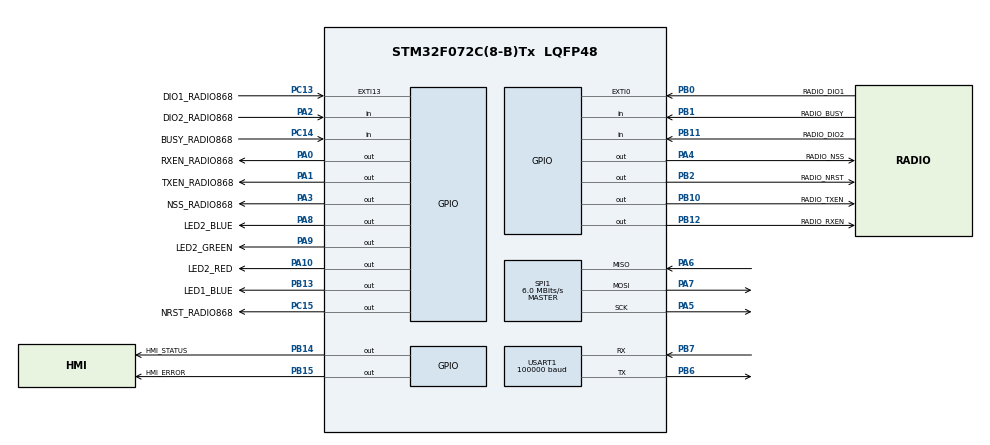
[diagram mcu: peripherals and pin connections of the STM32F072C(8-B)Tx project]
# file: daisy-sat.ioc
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Mcu.Family=STM32F0
Mcu.Name=STM32F072C(8-B)Tx
Mcu.Package=LQFP48
NVIC.EXTI0_1_IRQn=true\:0\:0\:false\:false\:false\:true\:false
NVIC.EXTI4_15_IRQn=true\:0\:0\:false\:false\:true\:true\:false
NVIC.USART1_IRQn=true\:0\:0\:false\:false\:false\:true\:false
PA0.GPIO_Label=RXEN_RADIO868
PA0.Signal=GPIO_Output
PA1.GPIO_Label=TXEN_RADIO868
PA1.Signal=GPIO_Output
PA10.GPIO_Label=LED2_RED
PA10.Signal=GPIO_Output
PA13.Mode=Serial_Wire
PA13.Signal=SYS_SWDIO
PA14.Mode=Serial_Wire
PA14.Signal=SYS_SWCLK
PA2.GPIO_Label=DIO2_RADIO868
PA2.GPIO_PuPd=GPIO_PULLUP
PA2.Signal=GPIO_Input
PA3.GPIO_Label=NSS_RADIO868
PA3.PinState=GPIO_PIN_SET
PA3.Signal=GPIO_Output
PA4.GPIO_Label=RADIO_NSS
PA4.PinState=GPIO_PIN_SET
PA4.Signal=GPIO_Output
PA5.Mode=Full_Duplex_Master
PA5.Signal=SPI1_SCK
PA6.GPIO_PuPd=GPIO_PULLUP
PA6.Mode=Full_Duplex_Master
PA6.Signal=SPI1_MISO
PA7.Mode=Full_Duplex_Master
PA7.Signal=SPI1_MOSI
PA8.GPIO_Label=LED2_BLUE
PA8.Signal=GPIO_Output
PA9.GPIO_Label=LED2_GREEN
PA9.Signal=GPIO_Output
PB0.GPIO_Label=RADIO_DIO1
PB0.GPIO_ModeDefaultEXTI=GPIO_MODE_IT_RISING
PB0.GPIO_PuPd=GPIO_PULLDOWN
PB0.Signal=GPXTI0
PB1.GPIO_Label=RADIO_BUSY
PB1.Signal=GPIO_Input
PB10.GPIO_Label=RADIO_TXEN
PB10.Signal=GPIO_Output
PB11.GPIO_Label=RADIO_DIO2
PB11.GPIO_PuPd=GPIO_PULLUP
PB11.Signal=GPIO_Input
PB12.GPIO_Label=RADIO_RXEN
PB12.Signal=GPIO_Output
PB13.GPIO_Label=LED1_BLUE
PB13.Signal=GPIO_Output
PB14.GPIO_Label=HMI_STATUS
PB14.Signal=GPIO_Output
PB15.GPIO_Label=HMI_ERROR
PB15.Signal=GPIO_Output
PB2.GPIO_Label=RADIO_NRST
PB2.Signal=GPIO_Output
PB6.Mode=Asynchronous
PB6.Signal=USART1_TX
PB7.GPIO_PuPd=GPIO_PULLUP
PB7.Mode=Asynchronous
PB7.Signal=USART1_RX
PC13.GPIO_Label=DIO1_RADIO868
PC13.GPIO_ModeDefaultEXTI=GPIO_MODE_IT_RISING
PC13.GPIO_PuPd=GPIO_PULLDOWN
PC13.Signal=GPXTI13
PC14-OSC32_IN.GPIO_Label=BUSY_RADIO868
PC14-OSC32_IN.Signal=GPIO_Input
PC15-OSC32_OUT.GPIO_Label=NRST_RADIO868
PC15-OSC32_OUT.Signal=GPIO_Output
ProjectManager.HeapSize=0x200
ProjectManager.StackSize=0x400
ProjectManager.TargetToolchain=STM32CubeIDE
RCC.AHBFreq_Value=48000000
RCC.APB1Freq_Value=48000000
RCC.APB1TimFreq_Value=48000000
RCC.HCLKFreq_Value=48000000
RCC.SYSCLKFreq_VALUE=48000000
RCC.SYSCLKSource=RCC_SYSCLKSOURCE_HSI48
SPI1.BaudRatePrescaler=SPI_BAUDRATEPRESCALER_8
SPI1.CalculateBaudRate=6.0 MBits/s
SPI1.DataSize=SPI_DATASIZE_8BIT
SPI1.Direction=SPI_DIRECTION_2LINES
SPI1.Mode=SPI_MODE_MASTER
SPI1.VirtualType=VM_MASTER
USART1.BaudRate=100000
USART1.OverrunDisableParam=ADVFEATURE_OVERRUN_ENABLE
USART1.Parity=PARITY_EVEN
USART1.RxPinLevelInvertParam=ADVFEATURE_RXINV_ENABLE
USART1.StopBits=STOPBITS_2
USART1.TxPinLevelInvertParam=ADVFEATURE_TXINV_ENABLE
USART1.VirtualMode-Asynchronous=VM_ASYNC
USART1.WordLength=WORDLENGTH_9B
VP_CRC_VS_CRC.Mode=CRC_Activate
board=custom

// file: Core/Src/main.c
/* USER CODE BEGIN Header */
/**
  ******************************************************************************
  * @file           : main.c
  * @brief          : Main program body
  ******************************************************************************
  * @attention
  *
  * <h2><center>&copy; Copyright (c) 2020 STMicroelectronics.
  * All rights reserved.</center></h2>
  *
  * This software component is licensed by ST under Ultimate Liberty license
  * SLA0044, the "License"; You may not use this file except in compliance with
  * the License. You may obtain a copy of the License at:
  *                             www.st.com/SLA0044
  *
  ******************************************************************************
  */
/* USER CODE END Header */
#include "main.h"

void SystemClock_Config(void);
static void MX_GPIO_Init(void);
static void MX_SPI1_Init(void);
static void MX_USART1_UART_Init(void);
static void MX_CRC_Init(void);

int main(void)
{

  /* MCU Configuration--------------------------------------------------------*/

  /* Reset of all peripherals, Initializes the Flash interface and the Systick. */

  LL_APB1_GRP2_EnableClock(LL_APB1_GRP2_PERIPH_SYSCFG);
  LL_APB1_GRP1_EnableClock(LL_APB1_GRP1_PERIPH_PWR);

  /* System interrupt init*/

  /* Configure the system clock */
  SystemClock_Config();

  /* Initialize all configured peripherals */
  MX_GPIO_Init();
  MX_SPI1_Init();
  MX_USART1_UART_Init();
  MX_CRC_Init();
  /* USER CODE BEGIN 2 */
  extern void RosalynSatSetup( void );
  RosalynSatSetup();
  /* USER CODE END 2 */

  /* Infinite loop */
  while (1)
  {

    /* USER CODE BEGIN 3 */
    extern void RosalynSatLoop( void );
    RosalynSatLoop();
  }
  /* USER CODE END 3 */
}

void SystemClock_Config(void)
{
  LL_FLASH_SetLatency(LL_FLASH_LATENCY_1);
  while(LL_FLASH_GetLatency() != LL_FLASH_LATENCY_1)
  {
  }
  LL_RCC_HSI48_Enable();

   /* Wait till HSI48 is ready */
  while(LL_RCC_HSI48_IsReady() != 1)
  {

  }
  LL_RCC_SetAHBPrescaler(LL_RCC_SYSCLK_DIV_1);
  LL_RCC_SetAPB1Prescaler(LL_RCC_APB1_DIV_1);
  LL_RCC_SetSysClkSource(LL_RCC_SYS_CLKSOURCE_HSI48);

   /* Wait till System clock is ready */
  while(LL_RCC_GetSysClkSource() != LL_RCC_SYS_CLKSOURCE_STATUS_HSI48)
  {

  }
  LL_Init1msTick(48000000);
  LL_SetSystemCoreClock(48000000);
  LL_RCC_SetUSARTClockSource(LL_RCC_USART1_CLKSOURCE_PCLK1);
}

static void MX_CRC_Init(void)
{

  /* Peripheral clock enable */
  LL_AHB1_GRP1_EnableClock(LL_AHB1_GRP1_PERIPH_CRC);

  LL_CRC_SetInputDataReverseMode(CRC, LL_CRC_INDATA_REVERSE_NONE);
  LL_CRC_SetOutputDataReverseMode(CRC, LL_CRC_OUTDATA_REVERSE_NONE);
  LL_CRC_SetInitialData(CRC, LL_CRC_DEFAULT_CRC_INITVALUE);

}

static void MX_SPI1_Init(void)
{

  LL_SPI_InitTypeDef SPI_InitStruct = {0};

  LL_GPIO_InitTypeDef GPIO_InitStruct = {0};

  /* Peripheral clock enable */
  LL_APB1_GRP2_EnableClock(LL_APB1_GRP2_PERIPH_SPI1);

  LL_AHB1_GRP1_EnableClock(LL_AHB1_GRP1_PERIPH_GPIOA);
  /**SPI1 GPIO Configuration
  PA5   ------> SPI1_SCK
  PA6   ------> SPI1_MISO
  PA7   ------> SPI1_MOSI
  */
  GPIO_InitStruct.Pin = LL_GPIO_PIN_5;
  GPIO_InitStruct.Mode = LL_GPIO_MODE_ALTERNATE;
  GPIO_InitStruct.Speed = LL_GPIO_SPEED_FREQ_HIGH;
  GPIO_InitStruct.OutputType = LL_GPIO_OUTPUT_PUSHPULL;
  GPIO_InitStruct.Pull = LL_GPIO_PULL_NO;
  GPIO_InitStruct.Alternate = LL_GPIO_AF_0;
  LL_GPIO_Init(GPIOA, &GPIO_InitStruct);

  GPIO_InitStruct.Pin = LL_GPIO_PIN_6;
  GPIO_InitStruct.Mode = LL_GPIO_MODE_ALTERNATE;
  GPIO_InitStruct.Speed = LL_GPIO_SPEED_FREQ_HIGH;
  GPIO_InitStruct.OutputType = LL_GPIO_OUTPUT_PUSHPULL;
  GPIO_InitStruct.Pull = LL_GPIO_PULL_UP;
  GPIO_InitStruct.Alternate = LL_GPIO_AF_0;
  LL_GPIO_Init(GPIOA, &GPIO_InitStruct);

  GPIO_InitStruct.Pin = LL_GPIO_PIN_7;
  GPIO_InitStruct.Mode = LL_GPIO_MODE_ALTERNATE;
  GPIO_InitStruct.Speed = LL_GPIO_SPEED_FREQ_HIGH;
  GPIO_InitStruct.OutputType = LL_GPIO_OUTPUT_PUSHPULL;
  GPIO_InitStruct.Pull = LL_GPIO_PULL_NO;
  GPIO_InitStruct.Alternate = LL_GPIO_AF_0;
  LL_GPIO_Init(GPIOA, &GPIO_InitStruct);

  /* SPI1 parameter configuration*/
  SPI_InitStruct.TransferDirection = LL_SPI_FULL_DUPLEX;
  SPI_InitStruct.Mode = LL_SPI_MODE_MASTER;
  SPI_InitStruct.DataWidth = LL_SPI_DATAWIDTH_8BIT;
  SPI_InitStruct.ClockPolarity = LL_SPI_POLARITY_LOW;
  SPI_InitStruct.ClockPhase = LL_SPI_PHASE_1EDGE;
  SPI_InitStruct.NSS = LL_SPI_NSS_SOFT;
  SPI_InitStruct.BaudRate = LL_SPI_BAUDRATEPRESCALER_DIV8;
  SPI_InitStruct.BitOrder = LL_SPI_MSB_FIRST;
  SPI_InitStruct.CRCCalculation = LL_SPI_CRCCALCULATION_DISABLE;
  SPI_InitStruct.CRCPoly = 7;
  LL_SPI_Init(SPI1, &SPI_InitStruct);
  LL_SPI_SetStandard(SPI1, LL_SPI_PROTOCOL_MOTOROLA);
  LL_SPI_EnableNSSPulseMgt(SPI1);

}

static void MX_USART1_UART_Init(void)
{

  LL_USART_InitTypeDef USART_InitStruct = {0};

  LL_GPIO_InitTypeDef GPIO_InitStruct = {0};

  /* Peripheral clock enable */
  LL_APB1_GRP2_EnableClock(LL_APB1_GRP2_PERIPH_USART1);

  LL_AHB1_GRP1_EnableClock(LL_AHB1_GRP1_PERIPH_GPIOB);
  /**USART1 GPIO Configuration
  PB6   ------> USART1_TX
  PB7   ------> USART1_RX
  */
  GPIO_InitStruct.Pin = LL_GPIO_PIN_6;
  GPIO_InitStruct.Mode = LL_GPIO_MODE_ALTERNATE;
  GPIO_InitStruct.Speed = LL_GPIO_SPEED_FREQ_HIGH;
  GPIO_InitStruct.OutputType = LL_GPIO_OUTPUT_PUSHPULL;
  GPIO_InitStruct.Pull = LL_GPIO_PULL_NO;
  GPIO_InitStruct.Alternate = LL_GPIO_AF_0;
  LL_GPIO_Init(GPIOB, &GPIO_InitStruct);

  GPIO_InitStruct.Pin = LL_GPIO_PIN_7;
  GPIO_InitStruct.Mode = LL_GPIO_MODE_ALTERNATE;
  GPIO_InitStruct.Speed = LL_GPIO_SPEED_FREQ_HIGH;
  GPIO_InitStruct.OutputType = LL_GPIO_OUTPUT_PUSHPULL;
  GPIO_InitStruct.Pull = LL_GPIO_PULL_UP;
  GPIO_InitStruct.Alternate = LL_GPIO_AF_0;
  LL_GPIO_Init(GPIOB, &GPIO_InitStruct);

  /* USART1 interrupt Init */
  NVIC_SetPriority(USART1_IRQn, 0);
  NVIC_EnableIRQ(USART1_IRQn);

  USART_InitStruct.BaudRate = 100000;
  USART_InitStruct.DataWidth = LL_USART_DATAWIDTH_9B;
  USART_InitStruct.StopBits = LL_USART_STOPBITS_2;
  USART_InitStruct.Parity = LL_USART_PARITY_EVEN;
  USART_InitStruct.TransferDirection = LL_USART_DIRECTION_TX_RX;
  USART_InitStruct.HardwareFlowControl = LL_USART_HWCONTROL_NONE;
  USART_InitStruct.OverSampling = LL_USART_OVERSAMPLING_16;
  LL_USART_Init(USART1, &USART_InitStruct);
  LL_USART_DisableIT_CTS(USART1);
  LL_USART_SetRXPinLevel(USART1, LL_USART_RXPIN_LEVEL_INVERTED);
  LL_USART_SetTXPinLevel(USART1, LL_USART_TXPIN_LEVEL_INVERTED);
  LL_USART_ConfigAsyncMode(USART1);
  LL_USART_Enable(USART1);

}

static void MX_GPIO_Init(void)
{
  LL_EXTI_InitTypeDef EXTI_InitStruct = {0};
  LL_GPIO_InitTypeDef GPIO_InitStruct = {0};

  /* GPIO Ports Clock Enable */
  LL_AHB1_GRP1_EnableClock(LL_AHB1_GRP1_PERIPH_GPIOC);
  LL_AHB1_GRP1_EnableClock(LL_AHB1_GRP1_PERIPH_GPIOF);
  LL_AHB1_GRP1_EnableClock(LL_AHB1_GRP1_PERIPH_GPIOA);
  LL_AHB1_GRP1_EnableClock(LL_AHB1_GRP1_PERIPH_GPIOB);

  /**/
  LL_GPIO_ResetOutputPin(NRST_RADIO868_GPIO_Port, NRST_RADIO868_Pin);

  /**/
  LL_GPIO_ResetOutputPin(RXEN_RADIO868_GPIO_Port, RXEN_RADIO868_Pin);

  /**/
  LL_GPIO_ResetOutputPin(TXEN_RADIO868_GPIO_Port, TXEN_RADIO868_Pin);

  /**/
  LL_GPIO_ResetOutputPin(RADIO_NRST_GPIO_Port, RADIO_NRST_Pin);

  /**/
  LL_GPIO_ResetOutputPin(RADIO_TXEN_GPIO_Port, RADIO_TXEN_Pin);

  /**/
  LL_GPIO_ResetOutputPin(RADIO_RXEN_GPIO_Port, RADIO_RXEN_Pin);

  /**/
  LL_GPIO_ResetOutputPin(LED1_BLUE_GPIO_Port, LED1_BLUE_Pin);

  /**/
  LL_GPIO_ResetOutputPin(HMI_STATUS_GPIO_Port, HMI_STATUS_Pin);

  /**/
  LL_GPIO_ResetOutputPin(HMI_ERROR_GPIO_Port, HMI_ERROR_Pin);

  /**/
  LL_GPIO_ResetOutputPin(LED2_BLUE_GPIO_Port, LED2_BLUE_Pin);

  /**/
  LL_GPIO_ResetOutputPin(LED2_GREEN_GPIO_Port, LED2_GREEN_Pin);

  /**/
  LL_GPIO_ResetOutputPin(LED2_RED_GPIO_Port, LED2_RED_Pin);

  /**/
  LL_GPIO_SetOutputPin(NSS_RADIO868_GPIO_Port, NSS_RADIO868_Pin);

  /**/
  LL_GPIO_SetOutputPin(RADIO_NSS_GPIO_Port, RADIO_NSS_Pin);

  /**/
  LL_SYSCFG_SetEXTISource(LL_SYSCFG_EXTI_PORTC, LL_SYSCFG_EXTI_LINE13);

  /**/
  LL_SYSCFG_SetEXTISource(LL_SYSCFG_EXTI_PORTB, LL_SYSCFG_EXTI_LINE0);

  /**/
  LL_GPIO_SetPinPull(DIO1_RADIO868_GPIO_Port, DIO1_RADIO868_Pin, LL_GPIO_PULL_DOWN);

  /**/
  LL_GPIO_SetPinPull(RADIO_DIO1_GPIO_Port, RADIO_DIO1_Pin, LL_GPIO_PULL_DOWN);

  /**/
  LL_GPIO_SetPinMode(DIO1_RADIO868_GPIO_Port, DIO1_RADIO868_Pin, LL_GPIO_MODE_INPUT);

  /**/
  LL_GPIO_SetPinMode(RADIO_DIO1_GPIO_Port, RADIO_DIO1_Pin, LL_GPIO_MODE_INPUT);

  /**/
  EXTI_InitStruct.Line_0_31 = LL_EXTI_LINE_13;
  EXTI_InitStruct.LineCommand = ENABLE;
  EXTI_InitStruct.Mode = LL_EXTI_MODE_IT;
  EXTI_InitStruct.Trigger = LL_EXTI_TRIGGER_RISING;
  LL_EXTI_Init(&EXTI_InitStruct);

  /**/
  EXTI_InitStruct.Line_0_31 = LL_EXTI_LINE_0;
  EXTI_InitStruct.LineCommand = ENABLE;
  EXTI_InitStruct.Mode = LL_EXTI_MODE_IT;
  EXTI_InitStruct.Trigger = LL_EXTI_TRIGGER_RISING;
  LL_EXTI_Init(&EXTI_InitStruct);

  /**/
  GPIO_InitStruct.Pin = BUSY_RADIO868_Pin;
  GPIO_InitStruct.Mode = LL_GPIO_MODE_INPUT;
  GPIO_InitStruct.Pull = LL_GPIO_PULL_NO;
  LL_GPIO_Init(BUSY_RADIO868_GPIO_Port, &GPIO_InitStruct);

  /**/
  GPIO_InitStruct.Pin = NRST_RADIO868_Pin;
  GPIO_InitStruct.Mode = LL_GPIO_MODE_OUTPUT;
  GPIO_InitStruct.Speed = LL_GPIO_SPEED_FREQ_LOW;
  GPIO_InitStruct.OutputType = LL_GPIO_OUTPUT_PUSHPULL;
  GPIO_InitStruct.Pull = LL_GPIO_PULL_NO;
  LL_GPIO_Init(NRST_RADIO868_GPIO_Port, &GPIO_InitStruct);

  /**/
  GPIO_InitStruct.Pin = LL_GPIO_PIN_0;
  GPIO_InitStruct.Mode = LL_GPIO_MODE_ANALOG;
  GPIO_InitStruct.Pull = LL_GPIO_PULL_NO;
  LL_GPIO_Init(GPIOF, &GPIO_InitStruct);

  /**/
  GPIO_InitStruct.Pin = LL_GPIO_PIN_1;
  GPIO_InitStruct.Mode = LL_GPIO_MODE_ANALOG;
  GPIO_InitStruct.Pull = LL_GPIO_PULL_NO;
  LL_GPIO_Init(GPIOF, &GPIO_InitStruct);

  /**/
  GPIO_InitStruct.Pin = RXEN_RADIO868_Pin;
  GPIO_InitStruct.Mode = LL_GPIO_MODE_OUTPUT;
  GPIO_InitStruct.Speed = LL_GPIO_SPEED_FREQ_LOW;
  GPIO_InitStruct.OutputType = LL_GPIO_OUTPUT_PUSHPULL;
  GPIO_InitStruct.Pull = LL_GPIO_PULL_NO;
  LL_GPIO_Init(RXEN_RADIO868_GPIO_Port, &GPIO_InitStruct);

  /**/
  GPIO_InitStruct.Pin = TXEN_RADIO868_Pin;
  GPIO_InitStruct.Mode = LL_GPIO_MODE_OUTPUT;
  GPIO_InitStruct.Speed = LL_GPIO_SPEED_FREQ_LOW;
  GPIO_InitStruct.OutputType = LL_GPIO_OUTPUT_PUSHPULL;
  GPIO_InitStruct.Pull = LL_GPIO_PULL_NO;
  LL_GPIO_Init(TXEN_RADIO868_GPIO_Port, &GPIO_InitStruct);

  /**/
  GPIO_InitStruct.Pin = DIO2_RADIO868_Pin;
  GPIO_InitStruct.Mode = LL_GPIO_MODE_INPUT;
  GPIO_InitStruct.Pull = LL_GPIO_PULL_UP;
  LL_GPIO_Init(DIO2_RADIO868_GPIO_Port, &GPIO_InitStruct);

  /**/
  GPIO_InitStruct.Pin = NSS_RADIO868_Pin;
  GPIO_InitStruct.Mode = LL_GPIO_MODE_OUTPUT;
  GPIO_InitStruct.Speed = LL_GPIO_SPEED_FREQ_LOW;
  GPIO_InitStruct.OutputType = LL_GPIO_OUTPUT_PUSHPULL;
  GPIO_InitStruct.Pull = LL_GPIO_PULL_NO;
  LL_GPIO_Init(NSS_RADIO868_GPIO_Port, &GPIO_InitStruct);

  /**/
  GPIO_InitStruct.Pin = RADIO_NSS_Pin;
  GPIO_InitStruct.Mode = LL_GPIO_MODE_OUTPUT;
  GPIO_InitStruct.Speed = LL_GPIO_SPEED_FREQ_LOW;
  GPIO_InitStruct.OutputType = LL_GPIO_OUTPUT_PUSHPULL;
  GPIO_InitStruct.Pull = LL_GPIO_PULL_NO;
  LL_GPIO_Init(RADIO_NSS_GPIO_Port, &GPIO_InitStruct);

  /**/
  GPIO_InitStruct.Pin = RADIO_BUSY_Pin;
  GPIO_InitStruct.Mode = LL_GPIO_MODE_INPUT;
  GPIO_InitStruct.Pull = LL_GPIO_PULL_NO;
  LL_GPIO_Init(RADIO_BUSY_GPIO_Port, &GPIO_InitStruct);

  /**/
  GPIO_InitStruct.Pin = RADIO_NRST_Pin;
  GPIO_InitStruct.Mode = LL_GPIO_MODE_OUTPUT;
  GPIO_InitStruct.Speed = LL_GPIO_SPEED_FREQ_LOW;
  GPIO_InitStruct.OutputType = LL_GPIO_OUTPUT_PUSHPULL;
  GPIO_InitStruct.Pull = LL_GPIO_PULL_NO;
  LL_GPIO_Init(RADIO_NRST_GPIO_Port, &GPIO_InitStruct);

  /**/
  GPIO_InitStruct.Pin = RADIO_TXEN_Pin;
  GPIO_InitStruct.Mode = LL_GPIO_MODE_OUTPUT;
  GPIO_InitStruct.Speed = LL_GPIO_SPEED_FREQ_LOW;
  GPIO_InitStruct.OutputType = LL_GPIO_OUTPUT_PUSHPULL;
  GPIO_InitStruct.Pull = LL_GPIO_PULL_NO;
  LL_GPIO_Init(RADIO_TXEN_GPIO_Port, &GPIO_InitStruct);

  /**/
  GPIO_InitStruct.Pin = RADIO_DIO2_Pin;
  GPIO_InitStruct.Mode = LL_GPIO_MODE_INPUT;
  GPIO_InitStruct.Pull = LL_GPIO_PULL_UP;
  LL_GPIO_Init(RADIO_DIO2_GPIO_Port, &GPIO_InitStruct);

  /**/
  GPIO_InitStruct.Pin = RADIO_RXEN_Pin;
  GPIO_InitStruct.Mode = LL_GPIO_MODE_OUTPUT;
  GPIO_InitStruct.Speed = LL_GPIO_SPEED_FREQ_LOW;
  GPIO_InitStruct.OutputType = LL_GPIO_OUTPUT_PUSHPULL;
  GPIO_InitStruct.Pull = LL_GPIO_PULL_NO;
  LL_GPIO_Init(RADIO_RXEN_GPIO_Port, &GPIO_InitStruct);

  /**/
  GPIO_InitStruct.Pin = LED1_BLUE_Pin;
  GPIO_InitStruct.Mode = LL_GPIO_MODE_OUTPUT;
  GPIO_InitStruct.Speed = LL_GPIO_SPEED_FREQ_LOW;
  GPIO_InitStruct.OutputType = LL_GPIO_OUTPUT_PUSHPULL;
  GPIO_InitStruct.Pull = LL_GPIO_PULL_NO;
  LL_GPIO_Init(LED1_BLUE_GPIO_Port, &GPIO_InitStruct);

  /**/
  GPIO_InitStruct.Pin = HMI_STATUS_Pin;
  GPIO_InitStruct.Mode = LL_GPIO_MODE_OUTPUT;
  GPIO_InitStruct.Speed = LL_GPIO_SPEED_FREQ_LOW;
  GPIO_InitStruct.OutputType = LL_GPIO_OUTPUT_PUSHPULL;
  GPIO_InitStruct.Pull = LL_GPIO_PULL_NO;
  LL_GPIO_Init(HMI_STATUS_GPIO_Port, &GPIO_InitStruct);

  /**/
  GPIO_InitStruct.Pin = HMI_ERROR_Pin;
  GPIO_InitStruct.Mode = LL_GPIO_MODE_OUTPUT;
  GPIO_InitStruct.Speed = LL_GPIO_SPEED_FREQ_LOW;
  GPIO_InitStruct.OutputType = LL_GPIO_OUTPUT_PUSHPULL;
  GPIO_InitStruct.Pull = LL_GPIO_PULL_NO;
  LL_GPIO_Init(HMI_ERROR_GPIO_Port, &GPIO_InitStruct);

  /**/
  GPIO_InitStruct.Pin = LED2_BLUE_Pin;
  GPIO_InitStruct.Mode = LL_GPIO_MODE_OUTPUT;
  GPIO_InitStruct.Speed = LL_GPIO_SPEED_FREQ_LOW;
  GPIO_InitStruct.OutputType = LL_GPIO_OUTPUT_PUSHPULL;
  GPIO_InitStruct.Pull = LL_GPIO_PULL_NO;
  LL_GPIO_Init(LED2_BLUE_GPIO_Port, &GPIO_InitStruct);

  /**/
  GPIO_InitStruct.Pin = LED2_GREEN_Pin;
  GPIO_InitStruct.Mode = LL_GPIO_MODE_OUTPUT;
  GPIO_InitStruct.Speed = LL_GPIO_SPEED_FREQ_LOW;
  GPIO_InitStruct.OutputType = LL_GPIO_OUTPUT_PUSHPULL;
  GPIO_InitStruct.Pull = LL_GPIO_PULL_NO;
  LL_GPIO_Init(LED2_GREEN_GPIO_Port, &GPIO_InitStruct);

  /**/
  GPIO_InitStruct.Pin = LED2_RED_Pin;
  GPIO_InitStruct.Mode = LL_GPIO_MODE_OUTPUT;
  GPIO_InitStruct.Speed = LL_GPIO_SPEED_FREQ_LOW;
  GPIO_InitStruct.OutputType = LL_GPIO_OUTPUT_PUSHPULL;
  GPIO_InitStruct.Pull = LL_GPIO_PULL_NO;
  LL_GPIO_Init(LED2_RED_GPIO_Port, &GPIO_InitStruct);

  /**/
  GPIO_InitStruct.Pin = LL_GPIO_PIN_11;
  GPIO_InitStruct.Mode = LL_GPIO_MODE_ANALOG;
  GPIO_InitStruct.Pull = LL_GPIO_PULL_NO;
  LL_GPIO_Init(GPIOA, &GPIO_InitStruct);

  /**/
  GPIO_InitStruct.Pin = LL_GPIO_PIN_12;
  GPIO_InitStruct.Mode = LL_GPIO_MODE_ANALOG;
  GPIO_InitStruct.Pull = LL_GPIO_PULL_NO;
  LL_GPIO_Init(GPIOA, &GPIO_InitStruct);

  /**/
  GPIO_InitStruct.Pin = LL_GPIO_PIN_15;
  GPIO_InitStruct.Mode = LL_GPIO_MODE_ANALOG;
  GPIO_InitStruct.Pull = LL_GPIO_PULL_NO;
  LL_GPIO_Init(GPIOA, &GPIO_InitStruct);

  /**/
  GPIO_InitStruct.Pin = LL_GPIO_PIN_3;
  GPIO_InitStruct.Mode = LL_GPIO_MODE_ANALOG;
  GPIO_InitStruct.Pull = LL_GPIO_PULL_NO;
  LL_GPIO_Init(GPIOB, &GPIO_InitStruct);

  /**/
  GPIO_InitStruct.Pin = LL_GPIO_PIN_4;
  GPIO_InitStruct.Mode = LL_GPIO_MODE_ANALOG;
  GPIO_InitStruct.Pull = LL_GPIO_PULL_NO;
  LL_GPIO_Init(GPIOB, &GPIO_InitStruct);

  /**/
  GPIO_InitStruct.Pin = LL_GPIO_PIN_5;
  GPIO_InitStruct.Mode = LL_GPIO_MODE_ANALOG;
  GPIO_InitStruct.Pull = LL_GPIO_PULL_NO;
  LL_GPIO_Init(GPIOB, &GPIO_InitStruct);

  /**/
  GPIO_InitStruct.Pin = LL_GPIO_PIN_8;
  GPIO_InitStruct.Mode = LL_GPIO_MODE_ANALOG;
  GPIO_InitStruct.Pull = LL_GPIO_PULL_NO;
  LL_GPIO_Init(GPIOB, &GPIO_InitStruct);

  /**/
  GPIO_InitStruct.Pin = LL_GPIO_PIN_9;
  GPIO_InitStruct.Mode = LL_GPIO_MODE_ANALOG;
  GPIO_InitStruct.Pull = LL_GPIO_PULL_NO;
  LL_GPIO_Init(GPIOB, &GPIO_InitStruct);

  /* EXTI interrupt init*/
  NVIC_SetPriority(EXTI0_1_IRQn, 0);
  NVIC_EnableIRQ(EXTI0_1_IRQn);
  NVIC_SetPriority(EXTI4_15_IRQn, 0);
  NVIC_EnableIRQ(EXTI4_15_IRQn);

}

void Error_Handler(void)
{
  __disable_irq();
  while (1)
  {
  }
}

/************************ (C) COPYRIGHT STMicroelectronics *****END OF FILE****/
